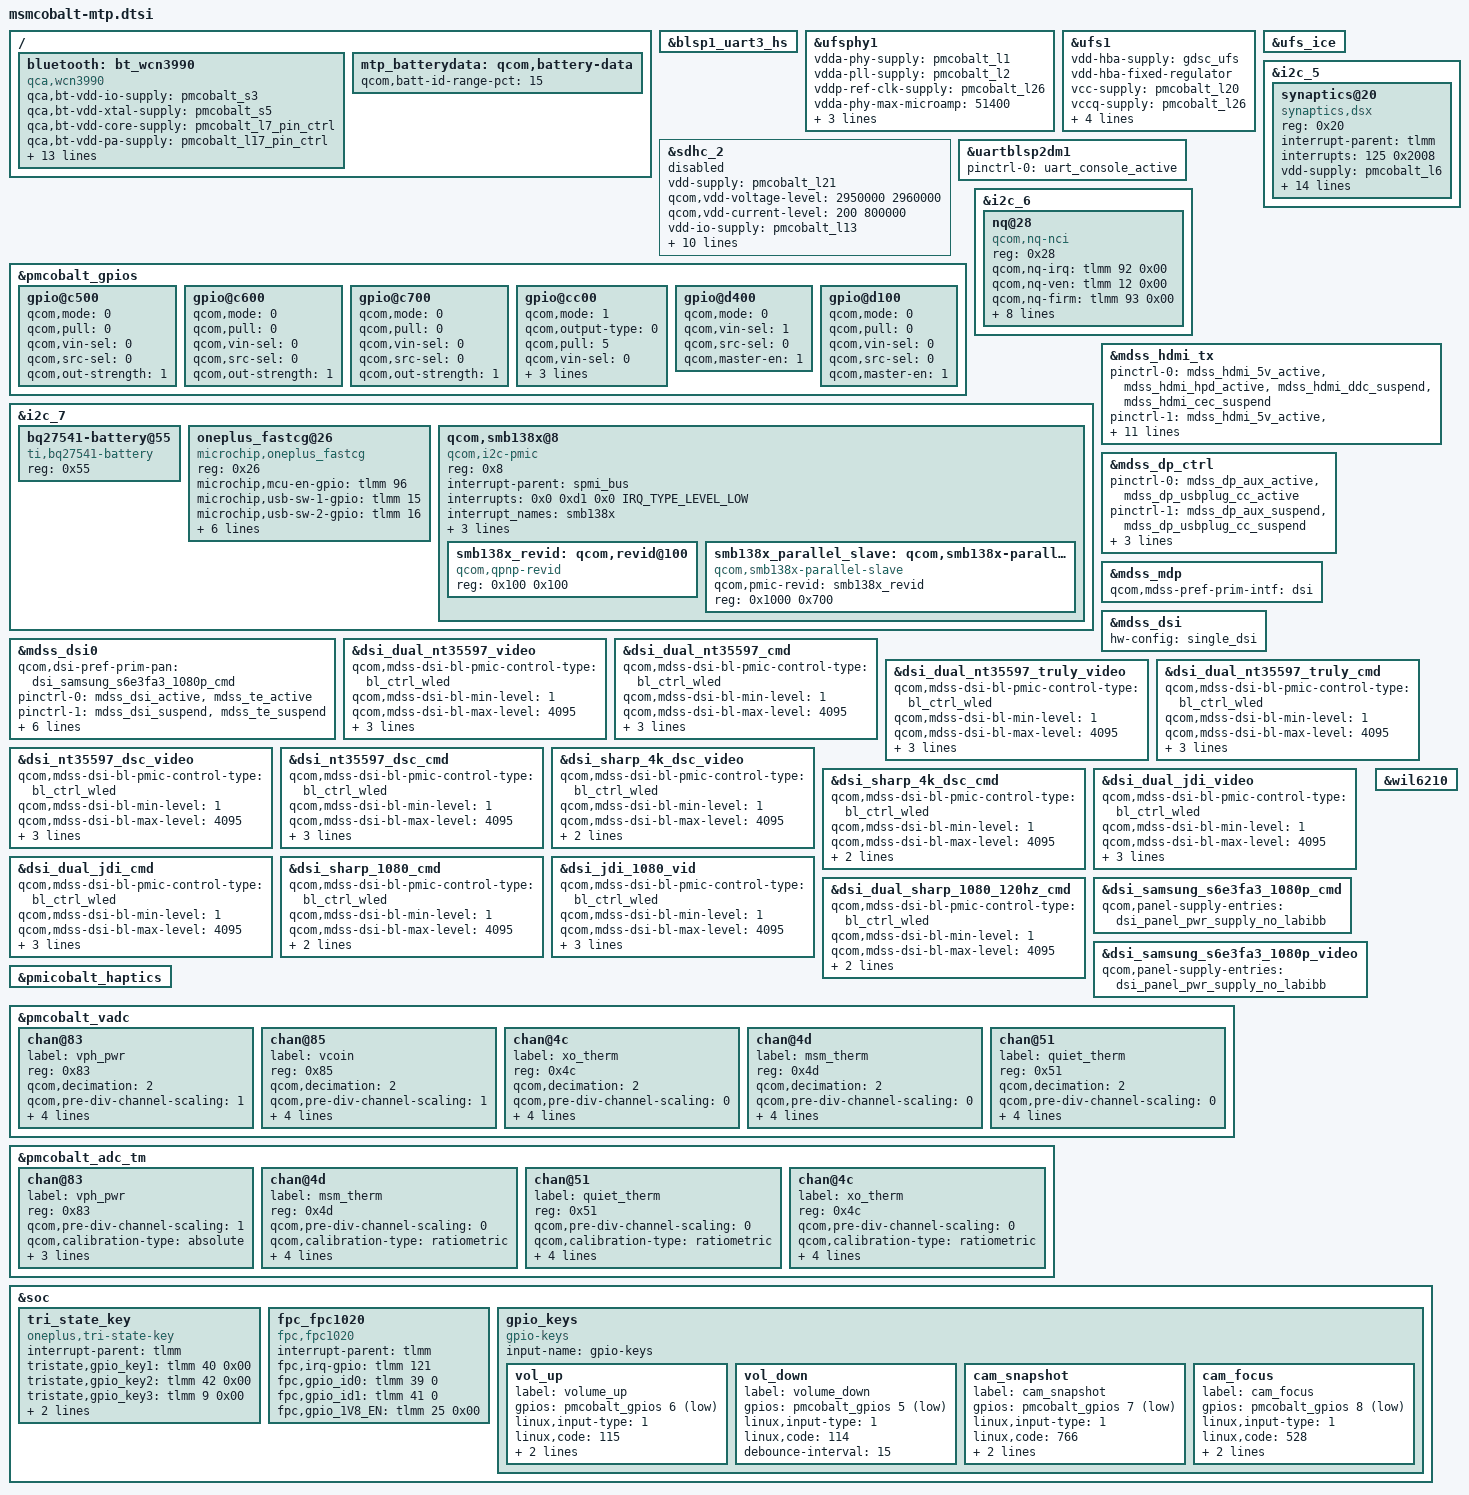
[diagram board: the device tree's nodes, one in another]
/* Copyright (c) 2016, The Linux Foundation. All rights reserved.
 *
 * This program is free software; you can redistribute it and/or modify
 * it under the terms of the GNU General Public License version 2 and
 * only version 2 as published by the Free Software Foundation.
 *
 * This program is distributed in the hope that it will be useful,
 * but WITHOUT ANY WARRANTY; without even the implied warranty of
 * MERCHANTABILITY or FITNESS FOR A PARTICULAR PURPOSE.  See the
 * GNU General Public License for more details.
 */

#include <dt-bindings/interrupt-controller/irq.h>
#include "msmcobalt-pinctrl.dtsi"
#include "msmcobalt-camera-sensor-mtp.dtsi"
/ {
	bluetooth: bt_wcn3990 {
		compatible = "qca,wcn3990";
		qca,bt-vdd-io-supply = <&pmcobalt_s3>;
		qca,bt-vdd-xtal-supply = <&pmcobalt_s5>;
		qca,bt-vdd-core-supply = <&pmcobalt_l7_pin_ctrl>;
		qca,bt-vdd-pa-supply = <&pmcobalt_l17_pin_ctrl>;
		qca,bt-vdd-ldo-supply = <&pmcobalt_l25_pin_ctrl>;
		qca,bt-chip-pwd-supply = <&pmicobalt_bob_pin1>;

		qca,bt-vdd-io-voltage-level = <1352000 1352000>;
		qca,bt-vdd-xtal-voltage-level = <2040000 2040000>;
		qca,bt-vdd-core-voltage-level = <1800000 1800000>;
		qca,bt-vdd-pa-voltage-level = <1304000 1304000>;
		qca,bt-vdd-ldo-voltage-level = <3312000 3312000>;
		qca,bt-chip-pwd-voltage-level = <3600000 3600000>;

		qca,bt-vdd-io-current-level = <1>; /* LPM/PFM */
		qca,bt-vdd-xtal-current-level = <1>; /* LPM/PFM */
		qca,bt-vdd-core-current-level = <1>; /* LPM/PFM */
		qca,bt-vdd-pa-current-level = <1>; /* LPM/PFM */
		qca,bt-vdd-ldo-current-level = <1>; /* LPM/PFM */
	};
};

&blsp1_uart3_hs {
	status = "ok";
};

&ufsphy1 {
	vdda-phy-supply = <&pmcobalt_l1>;
	vdda-pll-supply = <&pmcobalt_l2>;
	vddp-ref-clk-supply = <&pmcobalt_l26>;
	vdda-phy-max-microamp = <51400>;
	vdda-pll-max-microamp = <14600>;
	vddp-ref-clk-max-microamp = <100>;
	vddp-ref-clk-always-on;
	status = "ok";
};

&ufs1 {
	vdd-hba-supply = <&gdsc_ufs>;
	vdd-hba-fixed-regulator;
	vcc-supply = <&pmcobalt_l20>;
	vccq-supply = <&pmcobalt_l26>;
	vccq2-supply = <&pmcobalt_s4>;
	vcc-max-microamp = <750000>;
	vccq-max-microamp = <560000>;
	vccq2-max-microamp = <750000>;
	status = "ok";
};

&ufs_ice {
	status = "ok";
};

&sdhc_2 {
	vdd-supply = <&pmcobalt_l21>;
	qcom,vdd-voltage-level = <2950000 2960000>;
	qcom,vdd-current-level = <200 800000>;

	vdd-io-supply = <&pmcobalt_l13>;
	qcom,vdd-io-voltage-level = <1808000 2960000>;
	qcom,vdd-io-current-level = <200 22000>;

	pinctrl-names = "active", "sleep";
	pinctrl-0 = <&sdc2_clk_on  &sdc2_cmd_on &sdc2_data_on &sdc2_cd_on>;
	pinctrl-1 = <&sdc2_clk_off &sdc2_cmd_off &sdc2_data_off &sdc2_cd_off>;

	qcom,clk-rates = <400000 20000000 25000000
				50000000 100000000 200000000>;
	qcom,bus-speed-mode = "SDR12", "SDR25", "SDR50", "DDR50", "SDR104";
//#ifndef VENDOR_EDIT
	//cd-gpios = <&tlmm 95 0x1>;
//#endif
	status = "disable"; /* david@bsp modified. ori=ok */
};

&uartblsp2dm1 {
	status = "ok";
	pinctrl-names = "default";
	pinctrl-0 = <&uart_console_active>;
};

&pmcobalt_gpios {
	/* GPIO 6 for Vol+ Key */
	gpio@c500 {
		status = "okay";
		qcom,mode = <0>;
		qcom,pull = <0>;
		qcom,vin-sel = <0>;
		qcom,src-sel = <0>;
		qcom,out-strength = <1>;
	};

	/* GPIO 7 for Snapshot Key */
	gpio@c600 {
		status = "okay";
		qcom,mode = <0>;
		qcom,pull = <0>;
		qcom,vin-sel = <0>;
		qcom,src-sel = <0>;
		qcom,out-strength = <1>;
	};

	/* GPIO 8 for Focus Key */
	gpio@c700 {
		status = "okay";
		qcom,mode = <0>;
		qcom,pull = <0>;
		qcom,vin-sel = <0>;
		qcom,src-sel = <0>;
		qcom,out-strength = <1>;
	};

	gpio@cc00 { /* GPIO 13 */
		qcom,mode = <1>;
		qcom,output-type = <0>;
		qcom,pull = <5>;
		qcom,vin-sel = <0>;
		qcom,out-strength = <1>;
		qcom,src-sel = <3>;
		qcom,master-en = <1>;
		status = "okay";
	};

	/* GPIO 21 (NFC_CLK_REQ) */
	gpio@d400 {
		qcom,mode = <0>;
		qcom,vin-sel = <1>;
		qcom,src-sel = <0>;
		qcom,master-en = <1>;
		status = "okay";
	};

	/* GPIO 18 SMB138X */
	gpio@d100 {
		qcom,mode = <0>;
		qcom,pull = <0>;
		qcom,vin-sel = <0>;
		qcom,src-sel = <0>;
		qcom,master-en = <1>;
		status = "okay";
	};
};

&i2c_5 {
	status = "okay";
	synaptics@20 {
		compatible = "synaptics,dsx";
		reg = <0x20>;
		interrupt-parent = <&tlmm>;
		interrupts = <125 0x2008>;
		vdd-supply = <&pmcobalt_l6>;
		avdd-supply = <&pmcobalt_l28>;
		synaptics,vdd-voltage = <1808000 1808000>;
		synaptics,avdd-voltage = <3008000 3008000>;
		synaptics,vdd-current = <40000>;
		synaptics,avdd-current = <20000>;
		pinctrl-names = "pmx_ts_active", "pmx_ts_suspend";
		pinctrl-0 = <&ts_active>;
		pinctrl-1 = <&ts_int_suspend &ts_reset_suspend>;
		synaptics,display-coords = <0 0 1439 2559>;
		synaptics,panel-coords = <0 0 1439 2559>;
		synaptics,reset-gpio = <&tlmm 89 0x00>;
		synaptics,irq-gpio = <&tlmm 125 0x2008>;
		synaptics,disable-gpios;
		synaptics,fw-name = "PR1702898-s3528t_60QHD_00400001.img";
	};
};

&i2c_6 { /* BLSP1 QUP6 (NFC) */
	status = "okay";
	nq@28 {
		compatible = "qcom,nq-nci";
		reg = <0x28>;
		qcom,nq-irq = <&tlmm 92 0x00>;
		qcom,nq-ven = <&tlmm 12 0x00>;
		qcom,nq-firm = <&tlmm 93 0x00>;
		qcom,nq-clkreq = <&pmcobalt_gpios 21 0x00>;
		qcom,nq-esepwr = <&tlmm 116 0x00>;
		interrupt-parent = <&tlmm>;
		qcom,clk-src = "BBCLK3";
		interrupts = <92 0>;
		interrupt-names = "nfc_irq";
		pinctrl-names = "nfc_active", "nfc_suspend";
		pinctrl-0 = <&nfc_int_active &nfc_enable_active>;
		pinctrl-1 = <&nfc_int_suspend &nfc_enable_suspend>;
		clocks = <&clock_gcc clk_ln_bb_clk3_pin>;
		clock-names = "ref_clk";
	};
};

/* #ifdef VENDOR_EDIT */
/* david.liu@bsp, 20160926 Add dash charging */
&i2c_7 {
	bq27541-battery@55 {
		status = "ok";
		compatible = "ti,bq27541-battery";
		reg = <0x55>;
	};
	oneplus_fastcg@26{
		status = "ok";
		compatible = "microchip,oneplus_fastcg";
		reg = <0x26>;
		microchip,mcu-en-gpio = <&tlmm 96 0x00>;
		microchip,usb-sw-1-gpio = <&tlmm 15 0x00>;
		microchip,usb-sw-2-gpio = <&tlmm 16 0x00>;
		microchip,ap-clk = <&tlmm 79 0x00>;
		microchip,ap-data = <&tlmm 80 0x00>;

		pinctrl-names = "mux_fastchg_active", "mux_fastchg_suspend";
		pinctrl-0 = <&fastchg_active &usb_sw_active &ap_clk_active &ap_data_active>;
		pinctrl-1 = <&usb_sw_suspend &fastchg_suspend &ap_clk_suspend &ap_data_suspend>;
	};
};
/* #endif */

&mdss_hdmi_tx {
	pinctrl-names = "hdmi_hpd_active", "hdmi_ddc_active", "hdmi_cec_active",
				"hdmi_active", "hdmi_sleep";
	pinctrl-0 = <&mdss_hdmi_5v_active  &mdss_hdmi_hpd_active
			&mdss_hdmi_ddc_suspend &mdss_hdmi_cec_suspend>;
	pinctrl-1 = <&mdss_hdmi_5v_active &mdss_hdmi_hpd_active
			&mdss_hdmi_ddc_active &mdss_hdmi_cec_suspend>;
	pinctrl-2 = <&mdss_hdmi_5v_active &mdss_hdmi_hpd_active
			&mdss_hdmi_cec_active &mdss_hdmi_ddc_suspend>;
	pinctrl-3 = <&mdss_hdmi_5v_active &mdss_hdmi_hpd_active
			&mdss_hdmi_ddc_active &mdss_hdmi_cec_active>;
	pinctrl-4 = <&mdss_hdmi_5v_suspend &mdss_hdmi_hpd_suspend
			&mdss_hdmi_ddc_suspend &mdss_hdmi_cec_suspend>;
};

&mdss_dp_ctrl {
	pinctrl-names = "mdss_dp_active", "mdss_dp_sleep";
	pinctrl-0 = <&mdss_dp_aux_active &mdss_dp_usbplug_cc_active>;
	pinctrl-1 = <&mdss_dp_aux_suspend &mdss_dp_usbplug_cc_suspend>;
	qcom,aux-en-gpio = <&tlmm 77 0>;
	qcom,aux-sel-gpio = <&tlmm 78 0>;
	qcom,usbplug-cc-gpio = <&tlmm 38 0>;
};

&mdss_mdp {
	qcom,mdss-pref-prim-intf = "dsi";
};

&mdss_dsi {
//#ifndef VENDOR_EDIT
//	hw-config = "split_dsi";
//#else
	  hw-config = "single_dsi";
//#endif
};

&mdss_dsi0 {
//#ifndef VENDOR_EDIT
//	qcom,dsi-pref-prim-pan = <&dsi_dual_nt35597_video>;
//#else
	qcom,dsi-pref-prim-pan = <&dsi_samsung_s6e3fa3_1080p_cmd>;
//#endif
	pinctrl-names = "mdss_default", "mdss_sleep";
	pinctrl-0 = <&mdss_dsi_active &mdss_te_active>;
	pinctrl-1 = <&mdss_dsi_suspend &mdss_te_suspend>;
	qcom,platform-reset-gpio = <&tlmm 94 0>;
	qcom,platform-te-gpio = <&tlmm 11 0>; //VENDOR_EDIT 11
//	qcom,panel-mode-gpio = <&tlmm 91 0>; //VENDOR_EDIT
	qcom,platform-vci-gpio = <&tlmm 21 0>; //VENDOR_EDIT
	qcom,isp-1v1-en-gpio = <&tlmm 95 0>; //VENDOR_EDIT
	qcom,px-bp-gpio = <&tlmm 24 0>; //VENDOR_EDIT
	qcom,px-ext-clk = "BBCLK2";
};

//#ifndef VENDOR
/*
&mdss_dsi1 {
	qcom,dsi-pref-prim-pan = <&dsi_dual_nt35597_video>;
	pinctrl-names = "mdss_default", "mdss_sleep";
	pinctrl-0 = <&mdss_dsi_active &mdss_te_active>;
	pinctrl-1 = <&mdss_dsi_suspend &mdss_te_suspend>;
	qcom,platform-reset-gpio = <&tlmm 94 0>;
	qcom,platform-te-gpio = <&tlmm 10 0>;
	qcom,panel-mode-gpio = <&tlmm 91 0>;
};
&labibb {
	status = "ok";
	qpnp,qpnp-labibb-mode = "lcd";
};
*/
//#endif

&dsi_dual_nt35597_video {
	qcom,mdss-dsi-bl-pmic-control-type = "bl_ctrl_wled";
	qcom,mdss-dsi-bl-min-level = <1>;
	qcom,mdss-dsi-bl-max-level = <4095>;
	qcom,mdss-dsi-mode-sel-gpio-state = "dual_port";
	qcom,panel-supply-entries = <&dsi_panel_pwr_supply>;
};

&dsi_dual_nt35597_cmd {
	qcom,mdss-dsi-bl-pmic-control-type = "bl_ctrl_wled";
	qcom,mdss-dsi-bl-min-level = <1>;
	qcom,mdss-dsi-bl-max-level = <4095>;
	qcom,mdss-dsi-mode-sel-gpio-state = "dual_port";
	qcom,panel-supply-entries = <&dsi_panel_pwr_supply>;
};

&dsi_dual_nt35597_truly_video {
	qcom,mdss-dsi-bl-pmic-control-type = "bl_ctrl_wled";
	qcom,mdss-dsi-bl-min-level = <1>;
	qcom,mdss-dsi-bl-max-level = <4095>;
	qcom,mdss-dsi-mode-sel-gpio-state = "dual_port";
	qcom,panel-supply-entries = <&dsi_panel_pwr_supply>;
};

&dsi_dual_nt35597_truly_cmd {
	qcom,mdss-dsi-bl-pmic-control-type = "bl_ctrl_wled";
	qcom,mdss-dsi-bl-min-level = <1>;
	qcom,mdss-dsi-bl-max-level = <4095>;
	qcom,mdss-dsi-mode-sel-gpio-state = "dual_port";
	qcom,panel-supply-entries = <&dsi_panel_pwr_supply>;
};

&dsi_nt35597_dsc_video {
	qcom,mdss-dsi-bl-pmic-control-type = "bl_ctrl_wled";
	qcom,mdss-dsi-bl-min-level = <1>;
	qcom,mdss-dsi-bl-max-level = <4095>;
	qcom,mdss-dsi-mode-sel-gpio-state = "single_port";
	qcom,panel-supply-entries = <&dsi_panel_pwr_supply>;
};

&dsi_nt35597_dsc_cmd {
	qcom,mdss-dsi-bl-pmic-control-type = "bl_ctrl_wled";
	qcom,mdss-dsi-bl-min-level = <1>;
	qcom,mdss-dsi-bl-max-level = <4095>;
	qcom,mdss-dsi-mode-sel-gpio-state = "single_port";
	qcom,panel-supply-entries = <&dsi_panel_pwr_supply>;
};

&dsi_sharp_4k_dsc_video {
	qcom,mdss-dsi-bl-pmic-control-type = "bl_ctrl_wled";
	qcom,mdss-dsi-bl-min-level = <1>;
	qcom,mdss-dsi-bl-max-level = <4095>;
	qcom,panel-supply-entries = <&dsi_panel_pwr_supply>;
};

&dsi_sharp_4k_dsc_cmd {
	qcom,mdss-dsi-bl-pmic-control-type = "bl_ctrl_wled";
	qcom,mdss-dsi-bl-min-level = <1>;
	qcom,mdss-dsi-bl-max-level = <4095>;
	qcom,panel-supply-entries = <&dsi_panel_pwr_supply>;
};

&dsi_dual_jdi_video {
	qcom,mdss-dsi-bl-pmic-control-type = "bl_ctrl_wled";
	qcom,mdss-dsi-bl-min-level = <1>;
	qcom,mdss-dsi-bl-max-level = <4095>;
	qcom,5v-boost-gpio = <&tlmm 51 0>;
	qcom,panel-supply-entries = <&dsi_panel_pwr_supply>;
};

&dsi_dual_jdi_cmd {
	qcom,mdss-dsi-bl-pmic-control-type = "bl_ctrl_wled";
	qcom,mdss-dsi-bl-min-level = <1>;
	qcom,mdss-dsi-bl-max-level = <4095>;
	qcom,5v-boost-gpio = <&tlmm 51 0>;
	qcom,panel-supply-entries = <&dsi_panel_pwr_supply>;
};

&dsi_sharp_1080_cmd {
	qcom,mdss-dsi-bl-pmic-control-type = "bl_ctrl_wled";
	qcom,mdss-dsi-bl-min-level = <1>;
	qcom,mdss-dsi-bl-max-level = <4095>;
	qcom,panel-supply-entries = <&dsi_panel_pwr_supply>;
};

&dsi_jdi_1080_vid {
	qcom,mdss-dsi-bl-pmic-control-type = "bl_ctrl_wled";
	qcom,mdss-dsi-bl-min-level = <1>;
	qcom,mdss-dsi-bl-max-level = <4095>;
	qcom,panel-supply-entries = <&dsi_panel_pwr_supply_no_labibb>;
	qcom,5v-boost-gpio = <&tlmm 51 0>;
};
&dsi_dual_sharp_1080_120hz_cmd {
	qcom,mdss-dsi-bl-pmic-control-type = "bl_ctrl_wled";
	qcom,mdss-dsi-bl-min-level = <1>;
	qcom,mdss-dsi-bl-max-level = <4095>;
	qcom,panel-supply-entries = <&dsi_panel_pwr_supply>;
};

//#ifdef VENDOR_EDIT
&dsi_samsung_s6e3fa3_1080p_cmd {
	qcom,panel-supply-entries = <&dsi_panel_pwr_supply_no_labibb>;
};
//#ifdef VENDOR_EDIT
&dsi_samsung_s6e3fa3_1080p_video {
	qcom,panel-supply-entries = <&dsi_panel_pwr_supply_no_labibb>;
};
//#endif
&i2c_7 {
	status = "okay";
	qcom,smb138x@8 {
		compatible = "qcom,i2c-pmic";
		reg = <0x8>;
		#address-cells = <2>;
		#size-cells = <0>;
		interrupt-parent = <&spmi_bus>;
		interrupts = <0x0 0xd1 0x0 IRQ_TYPE_LEVEL_LOW>;
		interrupt_names = "smb138x";
		interrupt-controller;
		#interrupt-cells = <3>;
		qcom,periph-map = <0x10 0x11 0x12 0x13 0x14 0x16 0x36>;

		smb138x_revid: qcom,revid@100 {
			compatible = "qcom,qpnp-revid";
			reg = <0x100 0x100>;
		};

		smb138x_parallel_slave: qcom,smb138x-parallel-slave@1000 {
			compatible = "qcom,smb138x-parallel-slave";
			qcom,pmic-revid = <&smb138x_revid>;
			reg = <0x1000 0x700>;
		};
	};
};

&pmicobalt_haptics {
	status = "okay";
};

&pmcobalt_vadc {
	chan@83 {
		label = "vph_pwr";
		reg = <0x83>;
		qcom,decimation = <2>;
		qcom,pre-div-channel-scaling = <1>;
		qcom,calibration-type = "absolute";
		qcom,scale-function = <0>;
		qcom,hw-settle-time = <0>;
		qcom,fast-avg-setup = <0>;
	};

	chan@85 {
		label = "vcoin";
		reg = <0x85>;
		qcom,decimation = <2>;
		qcom,pre-div-channel-scaling = <1>;
		qcom,calibration-type = "absolute";
		qcom,scale-function = <0>;
		qcom,hw-settle-time = <0>;
		qcom,fast-avg-setup = <0>;
	};

	chan@4c {
		label = "xo_therm";
		reg = <0x4c>;
		qcom,decimation = <2>;
		qcom,pre-div-channel-scaling = <0>;
		qcom,calibration-type = "ratiometric";
		qcom,scale-function = <4>;
		qcom,hw-settle-time = <2>;
		qcom,fast-avg-setup = <0>;
	};

	chan@4d {
		label = "msm_therm";
		reg = <0x4d>;
		qcom,decimation = <2>;
		qcom,pre-div-channel-scaling = <0>;
		qcom,calibration-type = "ratiometric";
		qcom,scale-function = <2>;
		qcom,hw-settle-time = <2>;
		qcom,fast-avg-setup = <0>;
	};

	chan@51 {
		label = "quiet_therm";
		reg = <0x51>;
		qcom,decimation = <2>;
		qcom,pre-div-channel-scaling = <0>;
		qcom,calibration-type = "ratiometric";
		qcom,scale-function = <2>;
		qcom,hw-settle-time = <2>;
		qcom,fast-avg-setup = <0>;
	};
};

&pmcobalt_adc_tm {
	chan@83 {
		label = "vph_pwr";
		reg = <0x83>;
		qcom,pre-div-channel-scaling = <1>;
		qcom,calibration-type = "absolute";
		qcom,scale-function = <0>;
		qcom,hw-settle-time = <0>;
		qcom,btm-channel-number = <0x60>;
	};

	chan@4d {
		label = "msm_therm";
		reg = <0x4d>;
		qcom,pre-div-channel-scaling = <0>;
		qcom,calibration-type = "ratiometric";
		qcom,scale-function = <2>;
		qcom,hw-settle-time = <2>;
		qcom,btm-channel-number = <0x68>;
		qcom,thermal-node;
	};

	chan@51 {
		label = "quiet_therm";
		reg = <0x51>;
		qcom,pre-div-channel-scaling = <0>;
		qcom,calibration-type = "ratiometric";
		qcom,scale-function = <2>;
		qcom,hw-settle-time = <2>;
		qcom,btm-channel-number = <0x70>;
		qcom,thermal-node;
	};

	chan@4c {
		label = "xo_therm";
		reg = <0x4c>;
		qcom,pre-div-channel-scaling = <0>;
		qcom,calibration-type = "ratiometric";
		qcom,scale-function = <4>;
		qcom,hw-settle-time = <2>;
		qcom,btm-channel-number = <0x78>;
		qcom,thermal-node;
	};
};

&wil6210 {
	status = "ok";
};

&soc {


	tri_state_key {
                compatible = "oneplus,tri-state-key";
                status = "okay";
                interrupt-parent = <&tlmm>;
                tristate,gpio_key1 = <&tlmm 40 0x00>;
                tristate,gpio_key2 = <&tlmm 42 0x00>;
                tristate,gpio_key3 = <&tlmm 9 0x00>;

                pinctrl-names = "pmx_tri_state_key_active", "pmx_tri_state_key_suspend";
                pinctrl-0 = <&tri_state_key_active>;
                pinctrl-1 = <&tri_state_key_suspend>;
        };

	/*#ifdef VENDOR_EDIT //liuyan add for fingerprint register as platform device not spi device */
	fpc_fpc1020 {
		compatible = "fpc,fpc1020";
		interrupt-parent = <&tlmm>;
		/*fpc,reset-gpio    = <&tlmm 75 0>;*/
		fpc,irq-gpio    = <&tlmm 121 0>;
		fpc,gpio_id0    = <&tlmm 39 0>;
		fpc,gpio_id1    = <&tlmm 41 0>;
		fpc,gpio_1V8_EN = <&tlmm 25 0x00>;
		/*vcc_spi-supply  = <&pm8994_l13>;*/
		/*vdd_ana-supply  = <&pm8994_l13>;*/
		/*vdd_io-supply   = <&pm8994_s4>;*/
    /*
		pinctrl-names = "fpc1020_enable", "fpc1020_disable";
		pinctrl-0 = <&fpc_fpc1020_enable>;
		pinctrl-1 = <&fpc_fpc1020_disable>;*/
	};
	/* #endif VENDOR_EDIT //liuyan add for tri-state-key end*/

	gpio_keys {
		compatible = "gpio-keys";
		input-name = "gpio-keys";
		status = "okay";

		vol_up {
			label = "volume_up";
			gpios = <&pmcobalt_gpios 6 0x1>;
			linux,input-type = <1>;
			linux,code = <115>;
			gpio-key,wakeup;
			debounce-interval = <15>;
		};
		//#VENDOR_EDIT shankai@bsp ,add for volum_down support,2016,9-29
		vol_down {
			label = "volume_down";
			gpios = <&pmcobalt_gpios 5 0x1>;
			linux,input-type = <1>;
			linux,code = <114>;
			//gpio-key,wakeup;
			debounce-interval = <15>;
		};
		//#ENDIF
		cam_snapshot {
			label = "cam_snapshot";
			gpios = <&pmcobalt_gpios 7 0x1>;
			linux,input-type = <1>;
			linux,code = <766>;
			gpio-key,wakeup;
			debounce-interval = <15>;
		};

		cam_focus {
			label = "cam_focus";
			gpios = <&pmcobalt_gpios 8 0x1>;
			linux,input-type = <1>;
			linux,code = <528>;
			gpio-key,wakeup;
			debounce-interval = <15>;
		};
	};
};

/{
	mtp_batterydata: qcom,battery-data {
		qcom,batt-id-range-pct = <15>;
		#include "fg-gen3-batterydata-itech-3000mah.dtsi"
		#include "fg-gen3-batterydata-ascent-3450mah.dtsi"
	};
};
